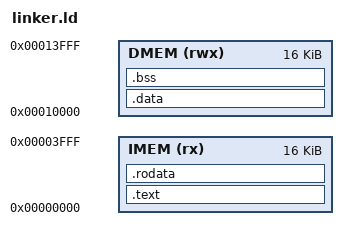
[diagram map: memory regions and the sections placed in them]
ENTRY(_start)

MEMORY
{
    IMEM (rx)  : ORIGIN = 0x00000000, LENGTH = 16K
    DMEM (rwx) : ORIGIN = 0x00010000, LENGTH = 16K
}

SECTIONS
{
    .text : {
        *(.text*)
    } > IMEM

    .rodata : {
        *(.rodata*)
    } > IMEM

    .data : {
        *(.data*)
    } > DMEM

    .bss : {
        *(.bss*)
        *(COMMON)
    } > DMEM
}
